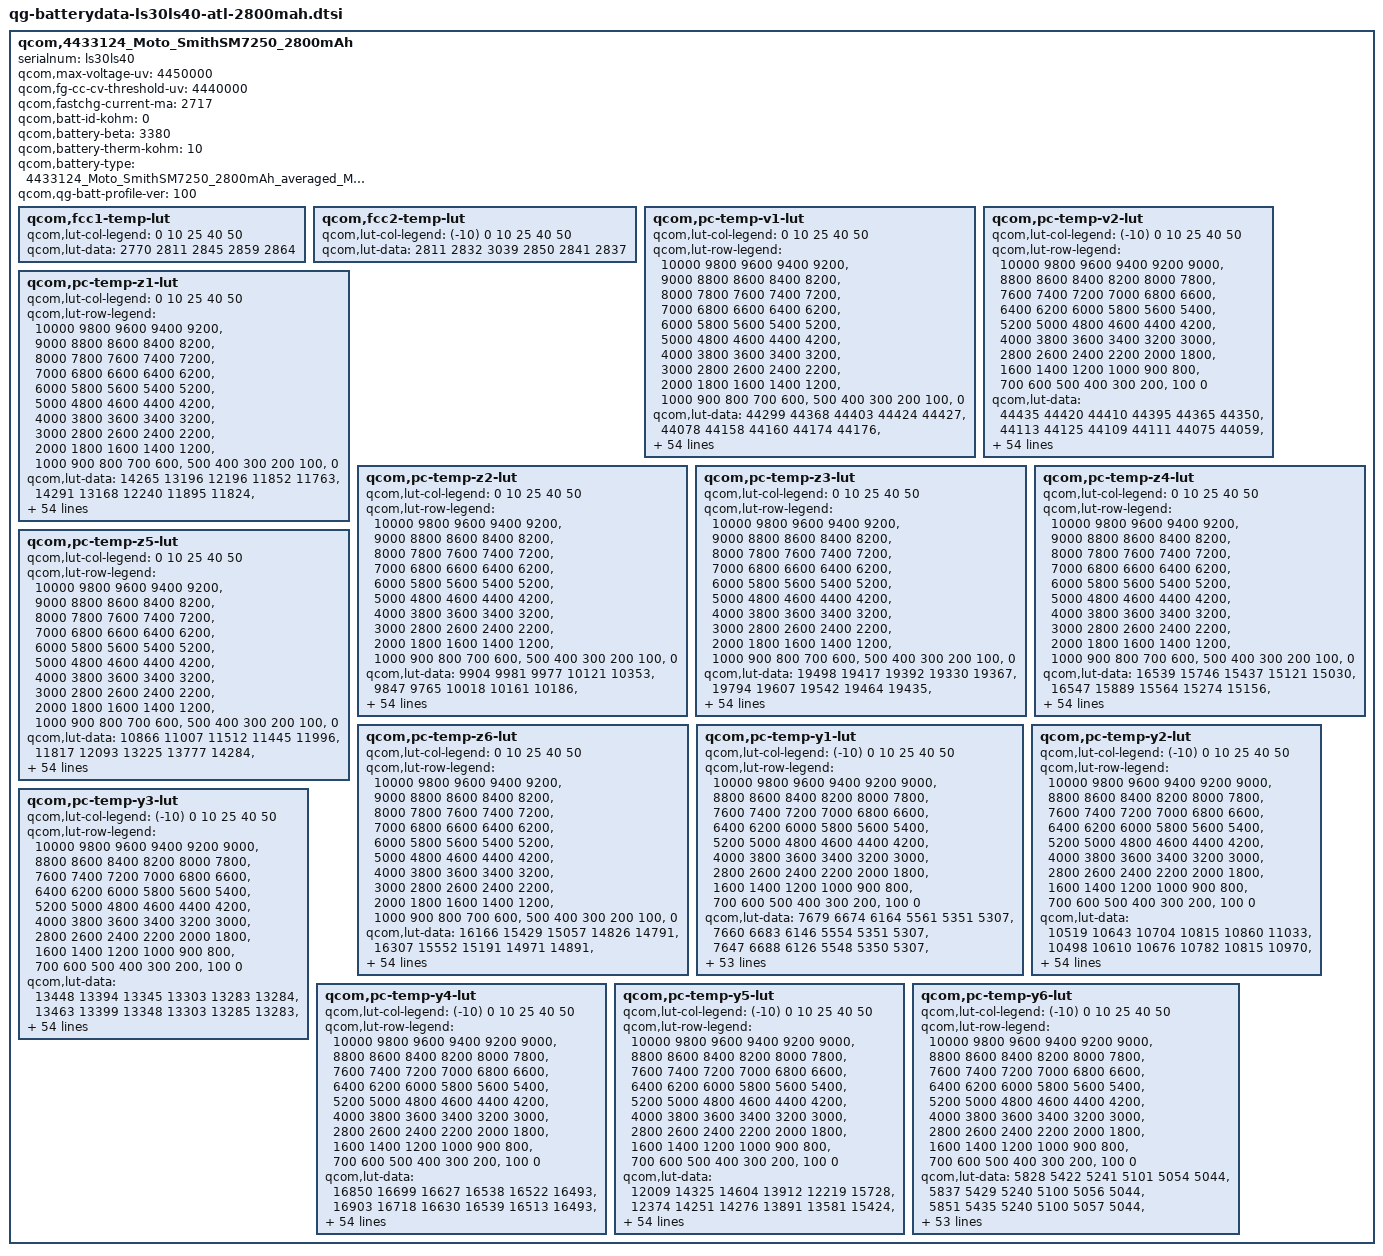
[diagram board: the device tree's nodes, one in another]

qcom,4433124_Moto_SmithSM7250_2800mAh {
    /* 4433124_Moto_SmithSM7250_2800mAh_averaged_MasterSlave_Mar20th2020 */
    serialnum = "ls30ls40";
    qcom,max-voltage-uv = <4450000>;
    qcom,fg-cc-cv-threshold-uv = <4440000>;
    qcom,fastchg-current-ma = <2717>;
    qcom,batt-id-kohm = <0>;
    qcom,battery-beta = <3380>;
    qcom,battery-therm-kohm = <10>;
    qcom,battery-type = "4433124_Moto_SmithSM7250_2800mAh_averaged_MasterSlave_Mar20th2020";
    qcom,qg-batt-profile-ver = <100>;

	qcom,fcc1-temp-lut {
		qcom,lut-col-legend = <0 10 25 40 50>;
		qcom,lut-data = <2770 2811 2845 2859 2864>;
	};

	qcom,fcc2-temp-lut {
		qcom,lut-col-legend = <(-10) 0 10 25 40 50>;
		qcom,lut-data = <2811 2832 3039 2850 2841 2837>;
	};

	qcom,pc-temp-v1-lut {
		qcom,lut-col-legend = <0 10 25 40 50>;
		qcom,lut-row-legend = <10000 9800 9600 9400 9200>,
			<9000 8800 8600 8400 8200>,
			<8000 7800 7600 7400 7200>,
			<7000 6800 6600 6400 6200>,
			<6000 5800 5600 5400 5200>,
			<5000 4800 4600 4400 4200>,
			<4000 3800 3600 3400 3200>,
			<3000 2800 2600 2400 2200>,
			<2000 1800 1600 1400 1200>,
			<1000 900 800 700 600>,
			<500 400 300 200 100>,
			<0>;
		qcom,lut-data = <44299 44368 44403 44424 44427>,
			<44078 44158 44160 44174 44176>,
			<43854 43934 43942 43951 43952>,
			<43631 43711 43731 43739 43741>,
			<43406 43490 43510 43522 43527>,
			<43172 43263 43284 43304 43310>,
			<42929 43026 43052 43079 43088>,
			<42684 42782 42811 42844 42855>,
			<42440 42537 42567 42603 42616>,
			<42195 42294 42325 42361 42376>,
			<41961 42054 42085 42118 42133>,
			<41738 41818 41847 41880 41895>,
			<41517 41587 41612 41648 41664>,
			<41296 41362 41382 41419 41437>,
			<41076 41143 41161 41197 41214>,
			<40862 40930 40946 40978 40995>,
			<40653 40721 40739 40769 40785>,
			<40452 40518 40538 40570 40585>,
			<40264 40326 40345 40378 40394>,
			<40083 40146 40166 40195 40212>,
			<39905 39966 39990 40018 40038>,
			<39734 39774 39788 39816 39839>,
			<39558 39575 39556 39572 39591>,
			<39346 39360 39332 39339 39354>,
			<39111 39107 39120 39145 39163>,
			<38929 38897 38931 38976 38998>,
			<38794 38777 38802 38846 38869>,
			<38686 38687 38707 38747 38771>,
			<38600 38602 38621 38656 38677>,
			<38531 38521 38536 38562 38573>,
			<38468 38447 38457 38473 38470>,
			<38409 38379 38381 38387 38380>,
			<38356 38316 38309 38305 38301>,
			<38305 38258 38242 38227 38224>,
			<38260 38206 38179 38155 38144>,
			<38216 38156 38119 38088 38066>,
			<38179 38111 38066 38024 37995>,
			<38139 38068 38016 37965 37929>,
			<38081 38008 37953 37893 37850>,
			<38000 37927 37866 37803 37750>,
			<37901 37829 37763 37698 37637>,
			<37781 37712 37653 37583 37516>,
			<37638 37572 37526 37452 37383>,
			<37468 37402 37366 37293 37222>,
			<37311 37247 37212 37150 37081>,
			<37195 37137 37101 37047 36985>,
			<37169 37104 37071 37012 36954>,
			<37134 37080 37049 36993 36934>,
			<37105 37059 37031 36975 36912>,
			<37070 37025 36988 36923 36852>,
			<36935 36859 36780 36679 36588>,
			<36527 36430 36349 36241 36147>,
			<35953 35846 35771 35662 35567>,
			<35153 35019 34985 34877 34781>,
			<33779 33708 33773 33671 33574>,
			<30000 30000 30000 30000 30000>;
	};

	qcom,pc-temp-v2-lut {
		qcom,lut-col-legend = <(-10) 0 10 25 40 50>;
		qcom,lut-row-legend = <10000 9800 9600 9400 9200 9000>,
			<8800 8600 8400 8200 8000 7800>,
			<7600 7400 7200 7000 6800 6600>,
			<6400 6200 6000 5800 5600 5400>,
			<5200 5000 4800 4600 4400 4200>,
			<4000 3800 3600 3400 3200 3000>,
			<2800 2600 2400 2200 2000 1800>,
			<1600 1400 1200 1000 900 800>,
			<700 600 500 400 300 200>,
			<100 0>;
		qcom,lut-data = <44435 44420 44410 44395 44365 44350>,
			<44113 44125 44109 44111 44075 44059>,
			<43823 43855 43832 43846 43805 43789>,
			<43573 43613 43582 43604 43559 43542>,
			<43360 43400 43355 43384 43338 43318>,
			<43146 43182 43115 43160 43113 43093>,
			<42913 42945 42860 42923 42877 42859>,
			<42674 42701 42599 42681 42637 42621>,
			<42435 42458 42336 42437 42396 42383>,
			<42194 42213 42074 42191 42153 42142>,
			<41954 41972 41815 41948 41913 41904>,
			<41715 41733 41560 41710 41675 41668>,
			<41477 41499 41311 41476 41441 41436>,
			<41233 41272 41067 41245 41211 41207>,
			<40985 41051 40833 41018 40987 40984>,
			<40739 40830 40605 40799 40771 40768>,
			<40494 40606 40381 40588 40563 40558>,
			<40250 40377 40158 40383 40363 40356>,
			<39999 40129 39916 40191 40174 40166>,
			<39741 39863 39665 40004 39993 39986>,
			<39515 39621 39435 39800 39797 39794>,
			<39334 39406 39209 39572 39581 39583>,
			<39173 39209 39002 39344 39363 39370>,
			<39008 39031 38829 39126 39147 39157>,
			<38844 38869 38675 38919 38937 38947>,
			<38692 38722 38539 38756 38772 38781>,
			<38552 38587 38416 38626 38644 38653>,
			<38421 38464 38305 38513 38532 38541>,
			<38298 38350 38205 38408 38427 38435>,
			<38182 38245 38113 38312 38330 38336>,
			<38081 38150 38027 38223 38243 38247>,
			<37994 38060 37950 38140 38165 38168>,
			<37920 37979 37878 38063 38089 38089>,
			<37862 37909 37805 37994 38012 38005>,
			<37814 37846 37731 37926 37934 37918>,
			<37769 37795 37651 37852 37846 37821>,
			<37726 37755 37561 37772 37751 37712>,
			<37681 37713 37455 37688 37653 37604>,
			<37626 37658 37337 37603 37556 37504>,
			<37562 37592 37271 37513 37458 37405>,
			<37480 37510 37220 37419 37363 37308>,
			<37350 37402 37161 37316 37267 37211>,
			<37217 37271 37091 37178 37131 37076>,
			<37109 37112 37015 37051 36992 36932>,
			<37002 36964 36957 36965 36919 36863>,
			<36902 36865 36926 36896 36852 36794>,
			<36850 36823 36880 36875 36832 36776>,
			<36802 36785 36852 36856 36823 36773>,
			<36751 36732 36818 36834 36801 36740>,
			<36685 36648 36752 36752 36707 36637>,
			<36575 36429 36564 36443 36404 36297>,
			<36319 35963 36094 35926 35898 35793>,
			<35805 35278 35394 35249 35244 35134>,
			<35008 34271 34408 34299 34352 34248>,
			<33815 32792 33004 33083 33124 32989>,
			<32074 29815 29518 29517 29516 29516>;
	};

	qcom,pc-temp-z1-lut {
		qcom,lut-col-legend = <0 10 25 40 50>;
		qcom,lut-row-legend = <10000 9800 9600 9400 9200>,
			<9000 8800 8600 8400 8200>,
			<8000 7800 7600 7400 7200>,
			<7000 6800 6600 6400 6200>,
			<6000 5800 5600 5400 5200>,
			<5000 4800 4600 4400 4200>,
			<4000 3800 3600 3400 3200>,
			<3000 2800 2600 2400 2200>,
			<2000 1800 1600 1400 1200>,
			<1000 900 800 700 600>,
			<500 400 300 200 100>,
			<0>;
		qcom,lut-data = <14265 13196 12196 11852 11763>,
			<14291 13168 12240 11895 11824>,
			<14299 13163 12236 11897 11826>,
			<14279 13155 12229 11897 11827>,
			<14238 13137 12221 11896 11827>,
			<14205 13115 12211 11892 11825>,
			<14177 13096 12201 11889 11823>,
			<14149 13077 12190 11888 11823>,
			<14122 13059 12182 11887 11822>,
			<14094 13041 12179 11885 11822>,
			<14070 13026 12177 11883 11820>,
			<14047 13014 12175 11882 11820>,
			<14027 13003 12173 11882 11820>,
			<14005 12999 12171 11881 11819>,
			<13985 12997 12170 11881 11820>,
			<13975 12995 12170 11882 11821>,
			<13972 12988 12170 11882 11822>,
			<13971 12978 12170 11884 11823>,
			<13966 12973 12171 11886 11825>,
			<13952 12971 12172 11887 11827>,
			<13946 12970 12174 11888 11829>,
			<13943 12971 12176 11890 11831>,
			<13942 12977 12179 11892 11833>,
			<13951 12982 12182 11894 11835>,
			<13971 12987 12186 11896 11836>,
			<13981 12993 12190 11899 11838>,
			<13977 12999 12195 11902 11841>,
			<13972 13005 12201 11906 11844>,
			<13970 13013 12208 11910 11847>,
			<13969 13022 12214 11914 11851>,
			<13969 13030 12221 11918 11854>,
			<13986 13036 12227 11922 11858>,
			<14005 13043 12234 11926 11862>,
			<14008 13050 12241 11931 11866>,
			<14005 13067 12249 11936 11870>,
			<14007 13082 12256 11941 11875>,
			<14030 13088 12263 11945 11878>,
			<14062 13095 12270 11949 11881>,
			<14080 13104 12278 11953 11883>,
			<14095 13122 12288 11957 11886>,
			<14115 13141 12297 11961 11888>,
			<14152 13156 12304 11965 11891>,
			<14192 13173 12311 11968 11894>,
			<14230 13201 12318 11971 11895>,
			<14236 13218 12330 11974 11897>,
			<14250 13229 12339 11977 11898>,
			<14240 13225 12338 11977 11898>,
			<14254 13232 12336 11977 11898>,
			<14266 13235 12339 11978 11900>,
			<14272 13271 12348 11982 11902>,
			<14346 13288 12361 11986 11906>,
			<14348 13303 12373 11993 11912>,
			<14377 13349 12390 12002 11919>,
			<14405 13373 12414 12017 11932>,
			<14405 13373 12414 12017 11932>,
			<14405 13373 12414 12017 11932>;
	};

	qcom,pc-temp-z2-lut {
		qcom,lut-col-legend = <0 10 25 40 50>;
		qcom,lut-row-legend = <10000 9800 9600 9400 9200>,
			<9000 8800 8600 8400 8200>,
			<8000 7800 7600 7400 7200>,
			<7000 6800 6600 6400 6200>,
			<6000 5800 5600 5400 5200>,
			<5000 4800 4600 4400 4200>,
			<4000 3800 3600 3400 3200>,
			<3000 2800 2600 2400 2200>,
			<2000 1800 1600 1400 1200>,
			<1000 900 800 700 600>,
			<500 400 300 200 100>,
			<0>;
		qcom,lut-data = <9904 9981 9977 10121 10353>,
			<9847 9765 10018 10161 10186>,
			<9807 9854 10010 10163 10229>,
			<9785 9884 9994 10146 10224>,
			<9768 9858 9968 10117 10210>,
			<9752 9823 9926 10049 10158>,
			<9737 9800 9890 10002 10113>,
			<9727 9780 9857 9989 10094>,
			<9723 9770 9837 9981 10082>,
			<9720 9765 9843 9982 10084>,
			<9730 9762 9865 9993 10104>,
			<9807 9771 9880 10006 10115>,
			<9870 9793 9889 10019 10114>,
			<9837 9809 9898 10033 10111>,
			<9767 9820 9912 10044 10120>,
			<9748 9828 9930 10055 10152>,
			<9762 9837 9945 10064 10166>,
			<9783 9846 9959 10070 10160>,
			<9803 9858 9972 10078 10150>,
			<9825 9876 9987 10090 10134>,
			<9831 9888 10004 10109 10113>,
			<9827 9886 10035 10159 10126>,
			<9823 9881 10092 10360 10364>,
			<9827 9884 10124 10514 10573>,
			<9837 9918 10118 10422 10492>,
			<9845 9946 10103 10226 10304>,
			<9850 9940 10078 10131 10229>,
			<9856 9927 10028 10081 10208>,
			<9861 9923 10004 10061 10210>,
			<9866 9923 10011 10133 10316>,
			<9871 9924 10026 10245 10471>,
			<9875 9925 10052 10269 10459>,
			<9880 9929 10096 10240 10266>,
			<9883 9932 10113 10209 10132>,
			<9887 9935 10087 10173 10096>,
			<9890 9938 10059 10139 10077>,
			<9892 9942 10062 10151 10093>,
			<9895 9947 10080 10210 10166>,
			<9898 9951 10099 10260 10247>,
			<9902 9957 10123 10293 10342>,
			<9906 9962 10144 10325 10422>,
			<9909 9966 10155 10366 10442>,
			<9913 9970 10162 10402 10449>,
			<9932 9976 10158 10405 10509>,
			<10097 10047 10174 10358 10476>,
			<10197 10125 10209 10258 10294>,
			<10254 10130 10187 10246 10305>,
			<10260 10162 10172 10260 10308>,
			<10254 10386 10127 10265 10344>,
			<10251 10585 10151 10312 10405>,
			<10252 10375 10192 10329 10215>,
			<10117 10277 10134 10139 10076>,
			<9946 10192 10074 10047 10031>,
			<9830 10008 10016 9963 9987>,
			<9830 10008 10016 9963 9987>,
			<9830 10008 10016 9963 9987>;
	};

	qcom,pc-temp-z3-lut {
		qcom,lut-col-legend = <0 10 25 40 50>;
		qcom,lut-row-legend = <10000 9800 9600 9400 9200>,
			<9000 8800 8600 8400 8200>,
			<8000 7800 7600 7400 7200>,
			<7000 6800 6600 6400 6200>,
			<6000 5800 5600 5400 5200>,
			<5000 4800 4600 4400 4200>,
			<4000 3800 3600 3400 3200>,
			<3000 2800 2600 2400 2200>,
			<2000 1800 1600 1400 1200>,
			<1000 900 800 700 600>,
			<500 400 300 200 100>,
			<0>;
		qcom,lut-data = <19498 19417 19392 19330 19367>,
			<19794 19607 19542 19464 19435>,
			<19974 19732 19583 19505 19474>,
			<20044 19791 19606 19527 19490>,
			<20087 19820 19631 19539 19500>,
			<20104 19836 19653 19547 19509>,
			<20112 19842 19661 19551 19513>,
			<20116 19846 19661 19548 19510>,
			<20114 19846 19661 19543 19505>,
			<20109 19837 19651 19537 19501>,
			<20112 19823 19625 19531 19497>,
			<20143 19803 19606 19524 19492>,
			<20168 19773 19597 19512 19482>,
			<20131 19754 19587 19499 19470>,
			<20046 19741 19574 19489 19462>,
			<20002 19733 19558 19482 19456>,
			<19987 19730 19545 19472 19448>,
			<19972 19728 19536 19456 19435>,
			<19944 19724 19527 19440 19419>,
			<19911 19712 19517 19429 19401>,
			<19903 19702 19507 19419 19381>,
			<19934 19707 19510 19420 19377>,
			<19970 19719 19535 19452 19409>,
			<19986 19730 19550 19478 19438>,
			<19999 19742 19548 19468 19430>,
			<20002 19750 19543 19442 19408>,
			<19993 19741 19534 19420 19386>,
			<19979 19721 19515 19398 19362>,
			<19966 19710 19499 19385 19349>,
			<19954 19703 19485 19389 19388>,
			<19944 19699 19475 19401 19450>,
			<19938 19697 19480 19416 19458>,
			<19932 19696 19498 19451 19442>,
			<19928 19696 19512 19468 19424>,
			<19924 19697 19521 19456 19408>,
			<19919 19697 19527 19437 19393>,
			<19914 19695 19521 19423 19381>,
			<19906 19688 19502 19410 19370>,
			<19897 19681 19493 19402 19366>,
			<19885 19673 19491 19396 19368>,
			<19870 19663 19489 19393 19372>,
			<19851 19650 19480 19396 19376>,
			<19827 19636 19466 19403 19383>,
			<19801 19626 19460 19409 19400>,
			<19681 19585 19448 19401 19397>,
			<19597 19537 19434 19371 19360>,
			<19357 19522 19425 19370 19346>,
			<19343 19499 19423 19363 19343>,
			<19333 19367 19403 19354 19337>,
			<19319 19331 19394 19349 19336>,
			<19320 19373 19405 19402 19384>,
			<19343 19384 19448 19421 19393>,
			<19349 19391 19468 19422 19393>,
			<19406 19561 19470 19421 19393>,
			<19406 19561 19470 19421 19393>,
			<19406 19561 19470 19421 19393>;
	};

	qcom,pc-temp-z4-lut {
		qcom,lut-col-legend = <0 10 25 40 50>;
		qcom,lut-row-legend = <10000 9800 9600 9400 9200>,
			<9000 8800 8600 8400 8200>,
			<8000 7800 7600 7400 7200>,
			<7000 6800 6600 6400 6200>,
			<6000 5800 5600 5400 5200>,
			<5000 4800 4600 4400 4200>,
			<4000 3800 3600 3400 3200>,
			<3000 2800 2600 2400 2200>,
			<2000 1800 1600 1400 1200>,
			<1000 900 800 700 600>,
			<500 400 300 200 100>,
			<0>;
		qcom,lut-data = <16539 15746 15437 15121 15030>,
			<16547 15889 15564 15274 15156>,
			<16516 15764 15442 15225 15141>,
			<16335 15632 15265 15090 15024>,
			<16021 15480 15157 15006 14945>,
			<15805 15338 15073 14953 14897>,
			<15649 15241 15008 14909 14858>,
			<15521 15164 14956 14865 14824>,
			<15423 15105 14916 14829 14797>,
			<15340 15059 14887 14812 14783>,
			<15238 15021 14865 14803 14775>,
			<15094 14987 14848 14794 14768>,
			<15003 14957 14835 14786 14761>,
			<15019 14936 14824 14779 14755>,
			<15055 14922 14816 14770 14747>,
			<15062 14910 14810 14760 14739>,
			<15029 14895 14802 14753 14731>,
			<15000 14879 14793 14748 14725>,
			<15003 14867 14785 14744 14720>,
			<15014 14857 14778 14739 14719>,
			<15013 14851 14772 14733 14719>,
			<14956 14854 14777 14734 14722>,
			<14902 14864 14814 14769 14756>,
			<14926 14887 14860 14817 14804>,
			<15001 14966 14922 14878 14858>,
			<15047 15027 14980 14941 14914>,
			<15071 15026 14986 14953 14926>,
			<15083 15018 14979 14951 14923>,
			<15080 15007 14969 14946 14917>,
			<15067 14990 14958 14925 14860>,
			<15051 14970 14943 14888 14772>,
			<15034 14950 14917 14846 14746>,
			<15016 14930 14876 14783 14738>,
			<14999 14912 14842 14753 14735>,
			<14984 14893 14814 14752 14736>,
			<14969 14878 14795 14752 14736>,
			<14953 14867 14792 14751 14735>,
			<14937 14858 14792 14749 14731>,
			<14920 14850 14792 14750 14730>,
			<14902 14843 14800 14769 14746>,
			<14884 14835 14808 14789 14763>,
			<14864 14822 14806 14784 14758>,
			<14841 14806 14802 14769 14743>,
			<14810 14788 14796 14760 14730>,
			<14787 14752 14768 14748 14716>,
			<14796 14729 14733 14735 14714>,
			<15056 14731 14726 14727 14716>,
			<15062 14740 14704 14708 14695>,
			<15065 14876 14695 14681 14666>,
			<15073 14900 14691 14670 14652>,
			<15055 14874 14718 14674 14671>,
			<15078 14885 14701 14682 14684>,
			<15080 14890 14691 14692 14695>,
			<15050 14733 14701 14705 14709>,
			<15050 14733 14701 14705 14709>,
			<15050 14733 14701 14705 14709>;
	};

	qcom,pc-temp-z5-lut {
		qcom,lut-col-legend = <0 10 25 40 50>;
		qcom,lut-row-legend = <10000 9800 9600 9400 9200>,
			<9000 8800 8600 8400 8200>,
			<8000 7800 7600 7400 7200>,
			<7000 6800 6600 6400 6200>,
			<6000 5800 5600 5400 5200>,
			<5000 4800 4600 4400 4200>,
			<4000 3800 3600 3400 3200>,
			<3000 2800 2600 2400 2200>,
			<2000 1800 1600 1400 1200>,
			<1000 900 800 700 600>,
			<500 400 300 200 100>,
			<0>;
		qcom,lut-data = <10866 11007 11512 11445 11996>,
			<11817 12093 13225 13777 14284>,
			<12470 12972 13799 14900 15754>,
			<12811 13523 14194 15808 16904>,
			<13054 13840 14752 16399 17818>,
			<13296 14103 15380 16779 18528>,
			<13524 14422 15942 17221 19273>,
			<13774 14747 16479 17995 20283>,
			<14058 14982 16874 18861 21391>,
			<14400 15176 17034 19491 22373>,
			<15003 15342 17138 20047 23364>,
			<16406 15508 17322 20257 23799>,
			<17403 15733 17783 20119 23512>,
			<17034 15973 18119 19960 23127>,
			<16242 16246 18079 20201 23463>,
			<16098 16606 17975 20966 24800>,
			<17027 17293 17996 21234 25381>,
			<17843 18212 18421 20515 24576>,
			<17472 18597 18914 19809 23207>,
			<16569 18681 19186 19827 21464>,
			<16487 18789 19468 20031 19304>,
			<19729 20147 20975 21225 19437>,
			<24141 23139 26755 30176 29836>,
			<27915 25382 30280 37445 39077>,
			<31716 27230 28460 33211 34851>,
			<32831 28244 25094 24051 24622>,
			<30852 26547 22402 19240 18947>,
			<28180 22906 19838 16538 15679>,
			<26424 21221 18078 15223 14236>,
			<24927 20520 16951 15023 16925>,
			<24233 20207 16263 15178 21205>,
			<23972 20358 16446 16352 21804>,
			<23824 20792 17467 20018 21012>,
			<23897 21422 18831 22025 20421>,
			<24207 22653 21653 22143 20201>,
			<24475 23732 24088 22199 20074>,
			<24641 24332 24027 22133 20076>,
			<24784 24804 23428 21828 20116>,
			<25010 24882 23241 21412 20120>,
			<25441 24768 23646 20661 19817>,
			<25642 24571 24018 19858 19479>,
			<24674 23622 22242 19233 19452>,
			<23894 22658 19229 18742 19620>,
			<24453 23469 19184 20200 24128>,
			<22099 23548 20004 20209 25181>,
			<18196 21562 20594 16958 17476>,
			<11496 19377 19323 17080 15805>,
			<11343 16579 20072 17413 16569>,
			<11242 11912 17929 18570 19134>,
			<11130 11470 17296 18815 20845>,
			<11218 11987 17230 27292 29180>,
			<11276 12114 19703 26768 27241>,
			<11268 12160 21594 24208 24186>,
			<11763 21377 20074 20886 20734>,
			<11763 21377 20074 20886 20734>,
			<11763 21377 20074 20886 20734>;
	};

	qcom,pc-temp-z6-lut {
		qcom,lut-col-legend = <0 10 25 40 50>;
		qcom,lut-row-legend = <10000 9800 9600 9400 9200>,
			<9000 8800 8600 8400 8200>,
			<8000 7800 7600 7400 7200>,
			<7000 6800 6600 6400 6200>,
			<6000 5800 5600 5400 5200>,
			<5000 4800 4600 4400 4200>,
			<4000 3800 3600 3400 3200>,
			<3000 2800 2600 2400 2200>,
			<2000 1800 1600 1400 1200>,
			<1000 900 800 700 600>,
			<500 400 300 200 100>,
			<0>;
		qcom,lut-data = <16166 15429 15057 14826 14791>,
			<16307 15552 15191 14971 14891>,
			<16359 15561 15154 14963 14899>,
			<16295 15559 15098 14923 14862>,
			<16168 15504 15065 14896 14837>,
			<16071 15434 15038 14878 14822>,
			<15994 15389 15014 14861 14808>,
			<15926 15353 14993 14841 14792>,
			<15869 15320 14973 14823 14778>,
			<15819 15291 14951 14812 14769>,
			<15772 15264 14929 14804 14763>,
			<15728 15234 14913 14796 14757>,
			<15689 15204 14901 14786 14749>,
			<15656 15183 14891 14775 14739>,
			<15627 15170 14879 14766 14731>,
			<15601 15160 14868 14757 14724>,
			<15575 15150 14857 14748 14716>,
			<15553 15140 14848 14738 14706>,
			<15539 15131 14840 14727 14696>,
			<15527 15120 14831 14718 14685>,
			<15520 15113 14824 14711 14674>,
			<15515 15116 14827 14712 14673>,
			<15512 15127 14855 14744 14705>,
			<15529 15145 14885 14779 14741>,
			<15572 15188 14911 14797 14758>,
			<15594 15219 14933 14810 14769>,
			<15599 15215 14933 14811 14770>,
			<15602 15204 14921 14800 14758>,
			<15599 15193 14909 14787 14746>,
			<15588 15184 14898 14779 14741>,
			<15577 15176 14888 14772 14738>,
			<15569 15168 14880 14765 14731>,
			<15560 15161 14873 14758 14720>,
			<15554 15155 14867 14751 14711>,
			<15548 15150 14862 14744 14703>,
			<15543 15145 14858 14737 14696>,
			<15538 15141 14851 14729 14688>,
			<15534 15137 14842 14720 14680>,
			<15530 15134 14840 14718 14677>,
			<15527 15132 14844 14723 14686>,
			<15522 15129 14847 14729 14694>,
			<15516 15123 14844 14728 14694>,
			<15507 15114 14835 14726 14692>,
			<15497 15108 14831 14726 14694>,
			<15444 15081 14815 14717 14688>,
			<15415 15051 14793 14696 14668>,
			<15407 15046 14786 14692 14662>,
			<15404 15040 14776 14680 14650>,
			<15405 15034 14762 14663 14634>,
			<15409 15032 14757 14656 14628>,
			<15417 15051 14777 14686 14662>,
			<15453 15069 14795 14702 14676>,
			<15473 15087 14805 14710 14683>,
			<15514 15121 14817 14719 14692>,
			<15514 15121 14817 14719 14692>,
			<15514 15121 14817 14719 14692>;
	};

	qcom,pc-temp-y1-lut {
		qcom,lut-col-legend = <(-10) 0 10 25 40 50>;
		qcom,lut-row-legend = <10000 9800 9600 9400 9200 9000>,
			<8800 8600 8400 8200 8000 7800>,
			<7600 7400 7200 7000 6800 6600>,
			<6400 6200 6000 5800 5600 5400>,
			<5200 5000 4800 4600 4400 4200>,
			<4000 3800 3600 3400 3200 3000>,
			<2800 2600 2400 2200 2000 1800>,
			<1600 1400 1200 1000 900 800>,
			<700 600 500 400 300 200>,
			<100 0>;
		qcom,lut-data = <7679 6674 6164 5561 5351 5307>,
			<7660 6683 6146 5554 5351 5307>,
			<7647 6688 6126 5548 5350 5307>,
			<7638 6689 6107 5542 5349 5306>,
			<7633 6689 6092 5536 5348 5305>,
			<7632 6688 6083 5531 5347 5305>,
			<7631 6686 6078 5526 5346 5305>,
			<7627 6682 6073 5522 5344 5304>,
			<7615 6679 6068 5519 5343 5304>,
			<7592 6675 6062 5515 5341 5303>,
			<7576 6672 6056 5513 5340 5303>,
			<7568 6665 6049 5512 5340 5303>,
			<7563 6658 6041 5511 5340 5303>,
			<7564 6658 6034 5510 5340 5303>,
			<7572 6659 6031 5508 5341 5304>,
			<7578 6659 6029 5508 5341 5305>,
			<7600 6658 6027 5508 5342 5305>,
			<7628 6658 6027 5509 5342 5305>,
			<7623 6657 6027 5510 5343 5305>,
			<7589 6651 6028 5512 5344 5306>,
			<7568 6650 6029 5514 5344 5307>,
			<7562 6655 6032 5516 5345 5307>,
			<7559 6659 6036 5519 5347 5308>,
			<7557 6657 6042 5522 5348 5309>,
			<7560 6653 6046 5526 5350 5310>,
			<7564 6652 6047 5530 5352 5312>,
			<7572 6654 6048 5533 5354 5314>,
			<7580 6657 6052 5537 5356 5316>,
			<7578 6663 6058 5541 5359 5318>,
			<7568 6670 6071 5546 5362 5320>,
			<7563 6674 6084 5551 5365 5322>,
			<7570 6678 6086 5557 5367 5324>,
			<7581 6681 6084 5562 5369 5326>,
			<7586 6684 6088 5567 5373 5328>,
			<7584 6689 6097 5573 5376 5330>,
			<7579 6690 6100 5577 5378 5332>,
			<7568 6695 6102 5580 5379 5333>,
			<7557 6698 6106 5583 5381 5335>,
			<7555 6704 6114 5586 5382 5337>,
			<7555 6713 6118 5588 5384 5339>,
			<7557 6717 6121 5592 5385 5339>,
			<7580 6740 6124 5596 5386 5340>,
			<7596 6746 6128 5597 5388 5342>,
			<7578 6740 6131 5599 5390 5343>,
			<7624 6754 6137 5603 5391 5344>,
			<7668 6771 6146 5606 5394 5347>,
			<7639 6758 6158 5611 5394 5347>,
			<7623 6767 6166 5611 5396 5347>,
			<7624 6773 6176 5612 5396 5348>,
			<7629 6789 6182 5612 5396 5349>,
			<7673 6788 6197 5614 5397 5349>,
			<7799 6796 6213 5624 5401 5353>,
			<7961 6898 6234 5636 5407 5359>,
			<8109 7053 6272 5651 5416 5365>,
			<8109 7053 6272 5651 5416 5365>,
			<8109 7053 6272 5651 5416 5365>;
	};

	qcom,pc-temp-y2-lut {
		qcom,lut-col-legend = <(-10) 0 10 25 40 50>;
		qcom,lut-row-legend = <10000 9800 9600 9400 9200 9000>,
			<8800 8600 8400 8200 8000 7800>,
			<7600 7400 7200 7000 6800 6600>,
			<6400 6200 6000 5800 5600 5400>,
			<5200 5000 4800 4600 4400 4200>,
			<4000 3800 3600 3400 3200 3000>,
			<2800 2600 2400 2200 2000 1800>,
			<1600 1400 1200 1000 900 800>,
			<700 600 500 400 300 200>,
			<100 0>;
		qcom,lut-data = <10519 10643 10704 10815 10860 11033>,
			<10498 10610 10676 10782 10815 10970>,
			<10476 10578 10648 10750 10771 10901>,
			<10453 10548 10622 10720 10731 10834>,
			<10435 10521 10597 10692 10695 10779>,
			<10423 10499 10572 10669 10665 10743>,
			<10416 10478 10548 10645 10640 10725>,
			<10412 10462 10533 10627 10619 10711>,
			<10412 10461 10525 10622 10607 10689>,
			<10414 10463 10520 10620 10598 10658>,
			<10417 10465 10518 10617 10592 10640>,
			<10422 10468 10521 10606 10596 10638>,
			<10428 10472 10533 10596 10603 10640>,
			<10435 10476 10545 10598 10599 10638>,
			<10443 10479 10552 10605 10589 10632>,
			<10454 10485 10560 10616 10590 10633>,
			<10485 10511 10580 10636 10632 10649>,
			<10520 10542 10606 10665 10692 10676>,
			<10527 10554 10623 10711 10738 10712>,
			<10528 10560 10643 10770 10783 10767>,
			<10530 10568 10658 10804 10835 10835>,
			<10534 10581 10672 10824 10912 10945>,
			<10540 10595 10678 10833 10964 11024>,
			<10545 10608 10682 10828 10941 11006>,
			<10548 10619 10689 10818 10889 10958>,
			<10551 10628 10701 10819 10879 10946>,
			<10552 10636 10712 10840 10923 10974>,
			<10554 10640 10717 10864 10969 11012>,
			<10557 10641 10715 10886 10987 11042>,
			<10562 10642 10710 10905 11001 11074>,
			<10565 10641 10704 10916 11024 11125>,
			<10570 10636 10700 10923 11068 11224>,
			<10575 10631 10697 10927 11116 11299>,
			<10566 10626 10688 10928 11166 11311>,
			<10533 10621 10673 10925 11210 11300>,
			<10498 10612 10660 10914 11207 11266>,
			<10466 10592 10648 10887 11155 11182>,
			<10432 10568 10628 10863 11096 11127>,
			<10399 10545 10599 10838 11032 11123>,
			<10363 10519 10584 10820 10978 11123>,
			<10288 10487 10575 10820 10973 11094>,
			<9924 10444 10565 10824 10981 11001>,
			<9696 10392 10550 10797 10947 10981>,
			<9675 10326 10532 10765 10874 10985>,
			<9666 10248 10516 10754 10852 10872>,
			<9661 10164 11641 10717 10762 10794>,
			<9658 9994 10494 10690 10726 10738>,
			<9656 9814 10439 10670 10796 10854>,
			<9654 9730 10411 10708 10847 10924>,
			<9652 9677 10386 10722 10828 10886>,
			<9649 9659 10326 10679 10751 10737>,
			<9647 9651 10192 10625 10698 10705>,
			<9647 9648 9953 10572 10644 10687>,
			<9646 9649 9679 10459 10546 10597>,
			<9646 9649 9679 10459 10546 10597>,
			<9646 9649 9679 10459 10546 10597>;
	};

	qcom,pc-temp-y3-lut {
		qcom,lut-col-legend = <(-10) 0 10 25 40 50>;
		qcom,lut-row-legend = <10000 9800 9600 9400 9200 9000>,
			<8800 8600 8400 8200 8000 7800>,
			<7600 7400 7200 7000 6800 6600>,
			<6400 6200 6000 5800 5600 5400>,
			<5200 5000 4800 4600 4400 4200>,
			<4000 3800 3600 3400 3200 3000>,
			<2800 2600 2400 2200 2000 1800>,
			<1600 1400 1200 1000 900 800>,
			<700 600 500 400 300 200>,
			<100 0>;
		qcom,lut-data = <13448 13394 13345 13303 13283 13284>,
			<13463 13399 13348 13303 13285 13283>,
			<13482 13406 13351 13305 13288 13283>,
			<13502 13413 13353 13306 13291 13283>,
			<13518 13419 13356 13307 13294 13283>,
			<13527 13421 13358 13308 13295 13284>,
			<13530 13421 13360 13309 13295 13285>,
			<13532 13421 13362 13310 13296 13286>,
			<13535 13422 13362 13311 13297 13288>,
			<13538 13425 13362 13312 13298 13290>,
			<13542 13427 13364 13313 13299 13292>,
			<13544 13428 13365 13320 13300 13293>,
			<13547 13429 13366 13326 13300 13294>,
			<13547 13432 13366 13328 13301 13295>,
			<13547 13443 13370 13328 13301 13296>,
			<13545 13448 13374 13329 13301 13296>,
			<13535 13449 13378 13332 13307 13296>,
			<13517 13450 13381 13334 13313 13296>,
			<13501 13445 13378 13334 13316 13298>,
			<13486 13430 13370 13333 13317 13303>,
			<13479 13417 13365 13332 13317 13305>,
			<13479 13409 13358 13329 13312 13303>,
			<13481 13402 13351 13325 13305 13300>,
			<13478 13397 13348 13316 13298 13294>,
			<13471 13393 13345 13305 13291 13285>,
			<13464 13390 13344 13302 13289 13283>,
			<13458 13387 13341 13301 13288 13284>,
			<13452 13385 13339 13300 13287 13285>,
			<13445 13384 13340 13302 13286 13284>,
			<13437 13383 13342 13305 13285 13283>,
			<13430 13383 13343 13305 13285 13282>,
			<13419 13384 13344 13305 13286 13283>,
			<13410 13385 13344 13305 13287 13284>,
			<13412 13384 13344 13306 13288 13285>,
			<13425 13381 13345 13306 13289 13285>,
			<13440 13382 13345 13306 13289 13285>,
			<13454 13387 13345 13306 13288 13282>,
			<13469 13394 13347 13306 13287 13281>,
			<13483 13398 13349 13306 13287 13281>,
			<13496 13402 13349 13306 13286 13282>,
			<13506 13406 13349 13306 13288 13285>,
			<13508 13409 13349 13308 13294 13288>,
			<13516 13412 13349 13306 13291 13286>,
			<13575 13412 13349 13303 13284 13279>,
			<13787 13414 13348 13304 13285 13283>,
			<13736 13418 13315 13306 13292 13287>,
			<13847 13418 13343 13316 13303 13295>,
			<14021 13441 13361 13330 13310 13299>,
			<14301 13493 13378 13336 13310 13299>,
			<14813 13616 13393 13335 13308 13298>,
			<16300 13871 13404 13324 13304 13294>,
			<20541 14925 13415 13325 13304 13295>,
			<31759 19488 13502 13336 13309 13300>,
			<65535 35272 14259 13355 13324 13315>,
			<65535 35272 14259 13355 13324 13315>,
			<65535 35272 14259 13355 13324 13315>;
	};

	qcom,pc-temp-y4-lut {
		qcom,lut-col-legend = <(-10) 0 10 25 40 50>;
		qcom,lut-row-legend = <10000 9800 9600 9400 9200 9000>,
			<8800 8600 8400 8200 8000 7800>,
			<7600 7400 7200 7000 6800 6600>,
			<6400 6200 6000 5800 5600 5400>,
			<5200 5000 4800 4600 4400 4200>,
			<4000 3800 3600 3400 3200 3000>,
			<2800 2600 2400 2200 2000 1800>,
			<1600 1400 1200 1000 900 800>,
			<700 600 500 400 300 200>,
			<100 0>;
		qcom,lut-data = <16850 16699 16627 16538 16522 16493>,
			<16903 16718 16630 16539 16513 16493>,
			<16963 16738 16633 16541 16507 16492>,
			<17020 16758 16635 16542 16503 16492>,
			<17069 16774 16638 16543 16502 16492>,
			<17099 16786 16640 16545 16502 16493>,
			<17114 16792 16641 16548 16504 16494>,
			<17125 16797 16645 16554 16508 16495>,
			<17136 16806 16654 16560 16511 16497>,
			<17145 16819 16669 16568 16515 16499>,
			<17154 16835 16685 16573 16519 16501>,
			<17164 16864 16704 16575 16525 16505>,
			<17172 16896 16731 16577 16533 16511>,
			<17167 16921 16761 16585 16543 16517>,
			<17145 16941 16799 16602 16555 16525>,
			<17132 16962 16834 16620 16564 16533>,
			<17144 16988 16861 16640 16569 16544>,
			<17161 17007 16883 16664 16574 16555>,
			<17133 16980 16862 16706 16594 16571>,
			<17008 16887 16795 16758 16630 16590>,
			<16929 16815 16762 16769 16641 16596>,
			<16917 16771 16699 16734 16639 16596>,
			<16908 16737 16641 16684 16634 16595>,
			<16893 16713 16617 16621 16598 16570>,
			<16871 16693 16601 16555 16529 16513>,
			<16852 16682 16599 16541 16510 16496>,
			<16838 16676 16602 16543 16513 16498>,
			<16826 16671 16607 16547 16518 16501>,
			<16814 16668 16610 16554 16528 16509>,
			<16801 16666 16610 16563 16544 16522>,
			<16796 16661 16610 16574 16559 16536>,
			<16808 16650 16614 16588 16578 16552>,
			<16826 16642 16617 16601 16589 16562>,
			<16832 16644 16618 16617 16591 16564>,
			<16835 16648 16618 16629 16591 16564>,
			<16839 16656 16619 16624 16587 16560>,
			<16853 16677 16622 16600 16572 16545>,
			<16872 16702 16620 16579 16557 16531>,
			<16887 16727 16618 16563 16542 16524>,
			<16899 16751 16619 16552 16530 16519>,
			<16920 16762 16620 16553 16532 16524>,
			<16976 16768 16622 16556 16545 16546>,
			<17007 16765 16617 16541 16528 16530>,
			<17006 16745 16607 16522 16493 16483>,
			<17009 16727 16606 16518 16493 16480>,
			<17007 16730 16543 16543 16507 16492>,
			<17030 16786 16620 16567 16535 16545>,
			<17058 16852 16658 16637 16695 16755>,
			<17102 16923 16717 16811 16836 16849>,
			<17172 17014 16794 16818 16801 16787>,
			<17384 17081 16840 16619 16603 16578>,
			<18390 17165 16795 16582 16554 16558>,
			<22568 19133 16918 16613 16576 16581>,
			<50498 38982 17673 16709 16640 16651>,
			<50498 38982 17673 16709 16640 16651>,
			<50498 38982 17673 16709 16640 16651>;
	};

	qcom,pc-temp-y5-lut {
		qcom,lut-col-legend = <(-10) 0 10 25 40 50>;
		qcom,lut-row-legend = <10000 9800 9600 9400 9200 9000>,
			<8800 8600 8400 8200 8000 7800>,
			<7600 7400 7200 7000 6800 6600>,
			<6400 6200 6000 5800 5600 5400>,
			<5200 5000 4800 4600 4400 4200>,
			<4000 3800 3600 3400 3200 3000>,
			<2800 2600 2400 2200 2000 1800>,
			<1600 1400 1200 1000 900 800>,
			<700 600 500 400 300 200>,
			<100 0>;
		qcom,lut-data = <12009 14325 14604 13912 12219 15728>,
			<12374 14251 14276 13891 13581 15424>,
			<12749 14143 13961 13694 14443 15058>,
			<13082 14008 13668 13409 14920 14687>,
			<13319 13850 13404 13124 15122 14370>,
			<13407 13672 13183 12928 15160 14164>,
			<13330 13294 13007 12734 14817 14022>,
			<13215 12855 12800 12525 14286 13915>,
			<13221 12673 12502 12350 14000 13932>,
			<13369 12562 12248 12136 13750 14121>,
			<13558 12488 12072 12063 13494 14207>,
			<13822 12428 11918 12400 13216 14042>,
			<14075 12388 11794 12769 12931 13780>,
			<14107 12550 11774 12686 12626 13537>,
			<14040 13201 11897 12369 12303 13222>,
			<14013 13842 12169 12223 12215 12917>,
			<14177 14405 13069 12196 12617 12583>,
			<14382 14945 14258 12183 13025 12355>,
			<14346 15444 14779 12259 13033 12421>,
			<14110 15916 15446 12530 12997 12729>,
			<13999 16049 15633 13096 13076 13238>,
			<14427 15714 15534 15017 14172 14674>,
			<14968 15334 15518 16439 15181 15859>,
			<14981 15229 15491 15835 15249 15719>,
			<14770 15177 15399 14607 15195 15241>,
			<14587 15146 15337 14104 15059 15050>,
			<14417 15015 15114 13890 14650 15041>,
			<14181 14949 14948 13801 14161 14956>,
			<13873 15013 15219 14118 13678 14438>,
			<13471 15073 15830 14648 13239 13650>,
			<13087 15203 16226 14826 13172 13454>,
			<12513 15624 16312 14881 13329 13544>,
			<11980 15937 16330 14948 13575 13702>,
			<12006 15611 16362 15134 14067 14209>,
			<12415 14962 16324 15425 14692 14909>,
			<12916 14855 16057 15913 15063 15027>,
			<13569 15243 15529 16772 15371 14843>,
			<14262 15513 15525 17123 15508 14718>,
			<14818 15476 15375 16634 15323 14913>,
			<15351 15374 15091 16053 15077 15392>,
			<15448 15237 14882 15872 15619 16280>,
			<12994 15022 14492 15740 17438 17822>,
			<11263 14698 14331 15610 17336 17741>,
			<11118 14092 14253 15341 16044 16535>,
			<10996 13453 13913 14620 13727 14874>,
			<10918 12792 17295 13121 13678 14402>,
			<10873 11846 12871 13582 15540 16012>,
			<10970 11534 13558 15332 16101 15328>,
			<11110 11365 13976 14958 14118 13713>,
			<11108 11428 14160 14317 13824 13709>,
			<10922 11362 13866 14998 15225 15252>,
			<9884 11284 13467 15169 16171 15979>,
			<9137 9772 12766 15823 15577 15115>,
			<8838 8960 11148 16673 16259 15827>,
			<8838 8960 11148 16673 16259 15827>,
			<8838 8960 11148 16673 16259 15827>;
	};

	qcom,pc-temp-y6-lut {
		qcom,lut-col-legend = <(-10) 0 10 25 40 50>;
		qcom,lut-row-legend = <10000 9800 9600 9400 9200 9000>,
			<8800 8600 8400 8200 8000 7800>,
			<7600 7400 7200 7000 6800 6600>,
			<6400 6200 6000 5800 5600 5400>,
			<5200 5000 4800 4600 4400 4200>,
			<4000 3800 3600 3400 3200 3000>,
			<2800 2600 2400 2200 2000 1800>,
			<1600 1400 1200 1000 900 800>,
			<700 600 500 400 300 200>,
			<100 0>;
		qcom,lut-data = <5828 5422 5241 5101 5054 5044>,
			<5837 5429 5240 5100 5056 5044>,
			<5851 5435 5240 5100 5057 5044>,
			<5865 5440 5239 5101 5058 5045>,
			<5876 5444 5239 5101 5059 5045>,
			<5880 5445 5239 5102 5061 5046>,
			<5879 5443 5239 5104 5062 5047>,
			<5877 5440 5239 5106 5063 5048>,
			<5876 5440 5241 5108 5065 5050>,
			<5876 5443 5243 5110 5067 5052>,
			<5876 5446 5247 5113 5069 5055>,
			<5876 5452 5253 5117 5071 5057>,
			<5875 5460 5260 5122 5074 5059>,
			<5872 5468 5268 5126 5076 5062>,
			<5865 5479 5280 5131 5080 5064>,
			<5857 5487 5292 5136 5083 5067>,
			<5852 5495 5302 5144 5088 5070>,
			<5846 5500 5310 5152 5094 5073>,
			<5828 5489 5302 5164 5103 5080>,
			<5784 5452 5277 5179 5113 5088>,
			<5762 5424 5264 5181 5116 5091>,
			<5761 5406 5241 5169 5112 5090>,
			<5761 5392 5220 5151 5105 5087>,
			<5759 5383 5212 5127 5088 5074>,
			<5753 5376 5207 5100 5064 5052>,
			<5749 5373 5206 5095 5057 5045>,
			<5748 5372 5206 5095 5058 5046>,
			<5747 5372 5208 5096 5059 5048>,
			<5747 5373 5210 5099 5061 5050>,
			<5749 5375 5214 5104 5065 5053>,
			<5751 5378 5217 5109 5069 5057>,
			<5759 5380 5220 5113 5076 5062>,
			<5771 5382 5223 5118 5080 5066>,
			<5788 5385 5225 5123 5081 5067>,
			<5812 5390 5228 5127 5082 5067>,
			<5842 5398 5231 5126 5082 5066>,
			<5878 5414 5235 5120 5077 5060>,
			<5921 5433 5240 5115 5072 5055>,
			<5969 5452 5245 5110 5068 5054>,
			<6025 5473 5248 5107 5064 5054>,
			<6079 5495 5251 5108 5066 5056>,
			<6124 5519 5253 5111 5074 5065>,
			<6181 5544 5253 5105 5068 5059>,
			<6271 5571 5252 5099 5053 5042>,
			<6395 5608 5254 5099 5054 5043>,
			<6502 5652 5207 5109 5063 5051>,
			<6626 5708 5261 5123 5080 5072>,
			<6800 5796 5294 5153 5131 5135>,
			<7065 5919 5332 5207 5170 5162>,
			<7540 6118 5376 5208 5159 5143>,
			<8874 6449 5413 5144 5100 5081>,
			<12458 7441 5448 5135 5086 5076>,
			<21646 11569 5686 5155 5098 5088>,
			<57043 28368 6709 5200 5128 5120>,
			<57043 28368 6709 5200 5128 5120>,
			<57043 28368 6709 5200 5128 5120>;
	};

};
